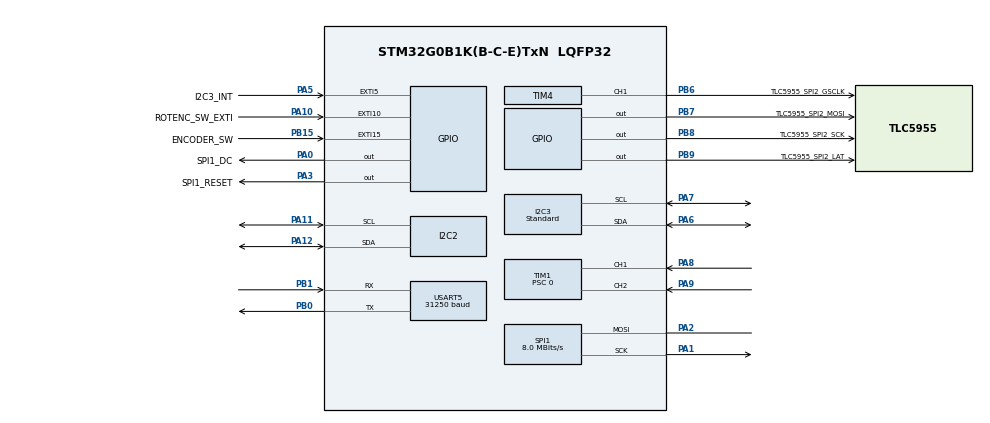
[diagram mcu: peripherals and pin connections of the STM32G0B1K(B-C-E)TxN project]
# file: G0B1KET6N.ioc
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Mcu.Family=STM32G0
PA6.Mode=I2C
PA11\ [PA9].Mode=I2C
Dma.SPI1_TX.0.MemInc=DMA_MINC_ENABLE
Dma.SPI1_TX.0.EventEnable=DISABLE
Dma.SPI1_TX.0.PeriphInc=DMA_PINC_DISABLE
TIM17.Prescaler=65535
RCC.CortexFreq_Value=64000000
VP_TIM17_VS_ClockSourceINT.Mode=Enable_Timer
SPI1.VirtualType=VM_MASTER
PA10.GPIO_PuPd=GPIO_PULLUP
PA12\ [PA10].Mode=I2C
PB7.GPIO_FM7=SYSCFG_FASTMODEPLUS_PB7
I2C2.Timing=0x10707DBC
PA0.GPIO_Label=SPI1_DC
PA14-BOOT0.Mode=Serial_Wire
TIM1.EncoderMode=TIM_ENCODERMODE_TI1
PB6.GPIO_Label=TLC5955_SPI2_GSCLK
Dma.SPI1_TX.0.SyncRequestNumber=1
PB15.Signal=GPXTI15
RCC.SYSCLKSource=RCC_SYSCLKSOURCE_PLLCLK
ProjectManager.StackSize=0x400
TIM17.AutoReloadPreload=TIM_AUTORELOAD_PRELOAD_ENABLE
TIM1.Prescaler=0
SPI1.CLKPolarity=SPI_POLARITY_HIGH
TIM4.OCFastMode_PWM-PWM\ Generation1\ CH1=TIM_OCFAST_ENABLE
SPI1.Direction=SPI_DIRECTION_1LINE
RCC.HCLKFreq_Value=64000000
PA12\ [PA10].Signal=I2C2_SDA
TIM4.Pulse-PWM\ Generation1\ CH1=256
TIM4.OCMode_PWM-PWM\ Generation1\ CH1=TIM_OCMODE_PWM2
PB6.Signal=S_TIM4_CH1
SPI1.CalculateBaudRate=8.0 MBits/s
RCC.AHBFreq_Value=64000000
PA14-BOOT0.Signal=SYS_SWCLK
RCC.HSE_VALUE=8000000
TIM1.IC2Polarity=TIM_ICPOLARITY_FALLING
NVIC.TIM3_TIM4_IRQn=true\:1\:0\:true\:false\:false\:true\:true
TIM3.Prescaler=32
PA5.GPIO_PuPd=GPIO_PULLUP
PA10.GPIO_Label=ROTENC_SW_EXTI
PB8.PinState=GPIO_PIN_SET
VP_SYS_VS_DBSignals.Mode=DisableDeadBatterySignals
PB7.Signal=GPIO_Output
PA8.Signal=S_TIM1_CH1
Dma.SPI1_TX.0.RequestNumber=1
TIM4.Period=512
TIM6.Period=64
Dma.SPI1_TX.0.Polarity=HAL_DMAMUX_REQ_GEN_RISING
PB7.PinState=GPIO_PIN_SET
PA0.Signal=GPIO_Output
PB7.GPIO_Label=TLC5955_SPI2_MOSI
Dma.SPI1_TX.0.Mode=DMA_CIRCULAR
PB9.Signal=GPIO_Output
Mcu.Package=LQFP32
PB1.Signal=USART5_RX
PA6.Signal=I2C3_SDA
Dma.SPI1_TX.0.SyncEnable=DISABLE
PB15.GPIO_PuPd=GPIO_PULLUP
PA10.GPIO_ModeDefaultEXTI=GPIO_MODE_IT_FALLING
PB6.GPIO_FM6=SYSCFG_FASTMODEPLUS_PB6
PB9.GPIO_PuPd=GPIO_PULLDOWN
PA10.Signal=GPXTI10
I2C3.Timing=0x10707DBC
PB9.GPIO_Speed=GPIO_SPEED_FREQ_VERY_HIGH
SH.S_TIM4_CH1.0=TIM4_CH1,PWM Generation1 CH1
TIM16.AutoReloadPreload=TIM_AUTORELOAD_PRELOAD_ENABLE
TIM1.Period=255
TIM16.Prescaler=1
PA6.GPIO_Speed=GPIO_SPEED_FREQ_VERY_HIGH
Dma.SPI1_TX.0.SyncSignalID=NONE
Dma.Request0=SPI1_TX
SPI1.BaudRatePrescaler=SPI_BAUDRATEPRESCALER_8
PB9.GPIO_FM9=SYSCFG_FASTMODEPLUS_PB9
VP_TIM3_VS_ClockSourceINT.Mode=Internal
NVIC.EXTI4_15_IRQn=true\:0\:0\:true\:false\:false\:true\:true
RCC.HSI48_VALUE=48000000
PA3.Signal=GPIO_Output
PB7.GPIO_Speed=GPIO_SPEED_FREQ_VERY_HIGH
PB7.GPIO_PuPd=GPIO_PULLDOWN
TIM4.Channel-PWM\ Generation1\ CH1=TIM_CHANNEL_1
PA5.GPIO_ModeDefaultEXTI=GPIO_MODE_IT_FALLING
TIM4.AutoReloadPreload=TIM_AUTORELOAD_PRELOAD_ENABLE
PA7.Mode=I2C
PB9.GPIO_Label=TLC5955_SPI2_LAT
PA11\ [PA9].GPIO_Speed=GPIO_SPEED_FREQ_VERY_HIGH
PA12\ [PA10].GPIO_Speed=GPIO_SPEED_FREQ_VERY_HIGH
PB8.GPIO_FM8=SYSCFG_FASTMODEPLUS_PB8
TIM1.CounterMode=TIM_COUNTERMODE_UP
PB6.GPIO_PuPd=GPIO_PULLDOWN
PB8.GPIO_PuPd=GPIO_PULLDOWN
TIM6.Prescaler=1
VP_TIM6_VS_ClockSourceINT.Mode=Enable_Timer
RCC.EXTERNAL_CLOCK_VALUE=48000
VP_TIM16_VS_ClockSourceINT.Mode=Enable_Timer
Dma.SPI1_TX.0.SignalID=NONE
PA13.Signal=SYS_SWDIO
TIM1.AutoReloadPreload=TIM_AUTORELOAD_PRELOAD_ENABLE
I2C3.GeneralCallMode=I2C_GENERALCALL_DISABLE
PB8.GPIO_Label=TLC5955_SPI2_SCK
SH.S_TIM1_CH1.0=TIM1_CH1,Encoder_Interface
ProjectManager.TargetToolchain=STM32CubeIDE
Dma.SPI1_TX.0.PeriphDataAlignment=DMA_PDATAALIGN_BYTE
Dma.SPI1_TX.0.Direction=DMA_MEMORY_TO_PERIPH
PA9.Signal=S_TIM1_CH2
Dma.SPI1_TX.0.SyncPolarity=HAL_DMAMUX_SYNC_NO_EVENT
RCC.USBFreq_Value=48000000
TIM4.Prescaler=1
RCC.LSE_VALUE=32768
PA1.Signal=SPI1_SCK
PA5.Signal=GPXTI5
PB15.GPIO_ModeDefaultEXTI=GPIO_MODE_IT_FALLING
PB0.Mode=Asynchronous
USART5.BaudRate=31250
board=custom
RCC.VCOOutputFreq_Value=128000000
PA7.GPIO_Speed=GPIO_SPEED_FREQ_VERY_HIGH
NVIC.SPI1_IRQn=true\:1\:0\:true\:false\:false\:true\:true
TIM1.TIM_MasterOutputTrigger=TIM_TRGO_RESET
TIM16.Period=512
PA1.Mode=Simplex_Bidirectional_Master
PB15.GPIO_Label=ENCODER_SW
SH.S_TIM1_CH2.0=TIM1_CH2,Encoder_Interface
SPI1.Mode=SPI_MODE_MASTER
RCC.ADCFreq_Value=64000000
TIM1.IC2Filter=0
Dma.SPI1_TX.0.Instance=DMA1_Channel1
PA13.Mode=Serial_Wire
PA11\ [PA9].Signal=I2C2_SCL
Mcu.Name=STM32G0B1K(B-C-E)TxN
SPI1.NSSPMode=SPI_NSS_PULSE_DISABLE
PA2.Signal=SPI1_MOSI
RCC.SYSCLKFreq_VALUE=64000000
PA5.GPIO_Label=I2C3_INT
TIM1.IC1Filter=0
USART5.VirtualMode=VM_ASYNC
TIM1.IC1Polarity=TIM_ICPOLARITY_FALLING
PB9.PinState=GPIO_PIN_SET
ProjectManager.HeapSize=0x200
Dma.SPI1_TX.0.MemDataAlignment=DMA_MDATAALIGN_BYTE
Dma.SPI1_TX.0.Priority=DMA_PRIORITY_LOW
PB1.Mode=Asynchronous
RCC.HSI_VALUE=16000000
VP_TIM4_VS_ClockSourceINT.Mode=Internal
PA2.Mode=Simplex_Bidirectional_Master
PB8.Signal=GPIO_Output
NVIC.DMA1_Channel1_IRQn=true\:2\:0\:true\:false\:false\:false\:true
PB6.GPIO_Speed=GPIO_SPEED_FREQ_VERY_HIGH
PB8.GPIO_Speed=GPIO_SPEED_FREQ_VERY_HIGH
PB0.Signal=USART5_TX
PA3.GPIO_Label=SPI1_RESET
PA7.Signal=I2C3_SCL
I2C3.I2C_Speed_Mode=I2C_Standard

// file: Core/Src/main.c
/* USER CODE BEGIN Header */
/**
  ******************************************************************************
  * @file           : main.c
  * @brief          : Main program body
  ******************************************************************************
  * @attention
  *
  * <h2><center>&copy; Copyright (c) 2021 STMicroelectronics.
  * All rights reserved.</center></h2>
  *
  * This software component is licensed by ST under BSD 3-Clause license,
  * the "License"; You may not use this file except in compliance with the
  * License. You may obtain a copy of the License at:
  *                        opensource.org/licenses/BSD-3-Clause
  *
  ******************************************************************************
  */
/* USER CODE END Header */
#include "main.h"
#include "dma.h"
#include "i2c.h"
#include "spi.h"
#include "tim.h"
#include "usart.h"
#include "gpio.h"

/* USER CODE BEGIN Includes */

#include <mainapp.hpp>
/* USER CODE END Includes */

void SystemClock_Config(void);

int main(void)
{

  /* MCU Configuration--------------------------------------------------------*/

  /* Reset of all peripherals, Initializes the Flash interface and the Systick. */

  LL_APB2_GRP1_EnableClock(LL_APB2_GRP1_PERIPH_SYSCFG);
  LL_APB1_GRP1_EnableClock(LL_APB1_GRP1_PERIPH_PWR);

  /* System interrupt init*/

  /** Disable the internal Pull-Up in Dead Battery pins of UCPD peripheral
  */
  LL_SYSCFG_DisableDBATT(LL_SYSCFG_UCPD1_STROBE | LL_SYSCFG_UCPD2_STROBE);

  /* Configure the system clock */
  SystemClock_Config();

  /* Initialize all configured peripherals */
  MX_GPIO_Init();
  MX_DMA_Init();
  MX_SPI1_Init();
  MX_TIM17_Init();
  MX_I2C3_Init();
  MX_I2C2_Init();
  MX_TIM1_Init();
  MX_USART5_UART_Init();
  MX_TIM3_Init();
  MX_TIM6_Init();
  MX_TIM16_Init();
  MX_TIM4_Init();
  /* USER CODE BEGIN 2 */
#ifdef USE_RTT
  SEGGER_RTT_ConfigUpBuffer(0, NULL, NULL, 0, SEGGER_RTT_MODE_BLOCK_IF_FIFO_FULL);
#endif

  mainapp();

  /* USER CODE END 2 */

  /* Infinite loop */
  while (1)
  {

  }
}

void SystemClock_Config(void)
{
  LL_FLASH_SetLatency(LL_FLASH_LATENCY_2);
  while(LL_FLASH_GetLatency() != LL_FLASH_LATENCY_2)
  {
  }

  /* HSI configuration and activation */
  LL_RCC_HSI_Enable();
  while(LL_RCC_HSI_IsReady() != 1)
  {
  }

  /* Main PLL configuration and activation */
  LL_RCC_PLL_ConfigDomain_SYS(LL_RCC_PLLSOURCE_HSI, LL_RCC_PLLM_DIV_1, 8, LL_RCC_PLLR_DIV_2);
  LL_RCC_PLL_Enable();
  LL_RCC_PLL_EnableDomain_SYS();
  while(LL_RCC_PLL_IsReady() != 1)
  {
  }

  /* Set AHB prescaler*/
  LL_RCC_SetAHBPrescaler(LL_RCC_SYSCLK_DIV_1);

  /* Sysclk activation on the main PLL */
  LL_RCC_SetSysClkSource(LL_RCC_SYS_CLKSOURCE_PLL);
  while(LL_RCC_GetSysClkSource() != LL_RCC_SYS_CLKSOURCE_STATUS_PLL)
  {
  }

  /* Set APB1 prescaler*/
  LL_RCC_SetAPB1Prescaler(LL_RCC_APB1_DIV_1);
  LL_Init1msTick(64000000);
  /* Update CMSIS variable (which can be updated also through SystemCoreClockUpdate function) */
  LL_SetSystemCoreClock(64000000);
  LL_RCC_SetTIMClockSource(LL_RCC_TIM1_CLKSOURCE_PCLK1);
  LL_RCC_SetI2CClockSource(LL_RCC_I2C2_CLKSOURCE_PCLK1);
}

void Error_Handler(void)
{
  __disable_irq();
  while (1)
  {
  }
}

/************************ (C) COPYRIGHT STMicroelectronics *****END OF FILE****/
